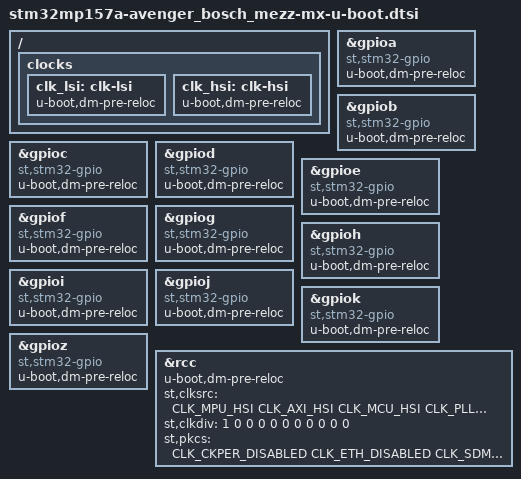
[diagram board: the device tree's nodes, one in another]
/* SPDX-License-Identifier: GPL-2.0+ OR BSD-3-Clause*/
/*
 * Copyright (C) 2019, STMicroelectronics - All Rights Reserved
 * Author: STM32CubeMX code generation for STMicroelectronics.
 */

#include <dt-bindings/clock/stm32mp1-clksrc.h>

#include "stm32mp157-u-boot.dtsi"
/* !!! log : Warning - DDR not configured: unknown DDR dtsi  !!! */
/*#include "???-ddr.dtsi"*/

/* USER CODE BEGIN includes */
/* USER CODE END includes */

/ {

	/* USER CODE BEGIN root */
	/* USER CODE END root */

clocks {
    /* USER CODE BEGIN clocks */
    /* USER CODE END clocks */

    clk_lsi: clk-lsi {
        /* USER CODE BEGIN clocks */
        /* USER CODE END clocks */
        u-boot,dm-pre-reloc;
    };
    clk_hsi: clk-hsi {
        /* USER CODE BEGIN clocks */
        /* USER CODE END clocks */
        u-boot,dm-pre-reloc;
    };
};

}; /*root*/

&gpioa {
    compatible = "st,stm32-gpio";
    u-boot,dm-pre-reloc;
};
&gpiob {
    compatible = "st,stm32-gpio";
    u-boot,dm-pre-reloc;
};
&gpioc {
    compatible = "st,stm32-gpio";
    u-boot,dm-pre-reloc;
};
&gpiod {
    compatible = "st,stm32-gpio";
    u-boot,dm-pre-reloc;
};
&gpioe {
    compatible = "st,stm32-gpio";
    u-boot,dm-pre-reloc;
};
&gpiof {
    compatible = "st,stm32-gpio";
    u-boot,dm-pre-reloc;
};
&gpiog {
    compatible = "st,stm32-gpio";
    u-boot,dm-pre-reloc;
};
&gpioh {
    compatible = "st,stm32-gpio";
    u-boot,dm-pre-reloc;
};
&gpioi {
    compatible = "st,stm32-gpio";
    u-boot,dm-pre-reloc;
};
&gpioj {
    compatible = "st,stm32-gpio";
    u-boot,dm-pre-reloc;
};
&gpiok {
    compatible = "st,stm32-gpio";
    u-boot,dm-pre-reloc;
};
&gpioz {
    compatible = "st,stm32-gpio";
    u-boot,dm-pre-reloc;
};

&rcc {
    u-boot,dm-pre-reloc;
    st,clksrc = <
        CLK_MPU_HSI
        CLK_AXI_HSI
        CLK_MCU_HSI
        CLK_PLL12_HSI
        CLK_PLL3_HSI
        CLK_PLL4_HSI
        CLK_RTC_LSI
        CLK_MCO1_DISABLED
        CLK_MCO2_DISABLED
    >;
    st,clkdiv = <
        1         /*MPU*/
        0         /*AXI*/
        0         /*MCU*/
        0         /*APB1*/
        0         /*APB2*/
        0         /*APB3*/
        0         /*APB4*/
        0         /*APB5*/
        0         /*RTC*/
        0         /*MCO1*/
        0         /*MCO2*/
    >;
    st,pkcs = <
        CLK_CKPER_DISABLED
        CLK_ETH_DISABLED
        CLK_SDMMC12_DISABLED
        CLK_STGEN_HSI
        CLK_USBPHY_DISABLED
        CLK_SPI2S1_DISABLED
        CLK_SPI2S23_DISABLED
        CLK_SPI45_DISABLED
        CLK_SPI6_DISABLED
        CLK_I2C46_DISABLED
        CLK_SDMMC3_DISABLED
        CLK_ADC_DISABLED
        CLK_CEC_DISABLED
        CLK_I2C12_PCLK1
        CLK_I2C35_DISABLED
        CLK_UART1_DISABLED
        CLK_UART24_DISABLED
        CLK_UART35_DISABLED
        CLK_UART6_DISABLED
        CLK_UART78_DISABLED
        CLK_SPDIF_DISABLED
        CLK_SAI1_DISABLED
        CLK_SAI2_DISABLED
        CLK_SAI3_DISABLED
        CLK_SAI4_DISABLED
        CLK_LPTIM1_DISABLED
        CLK_LPTIM23_DISABLED
        CLK_LPTIM45_DISABLED
    >;
};

&rcc{
    u-boot,dm-pre-reloc;

    /* USER CODE BEGIN rcc */
    /* USER CODE END rcc */
};

/* USER CODE BEGIN addons */
/* USER CODE END addons */

